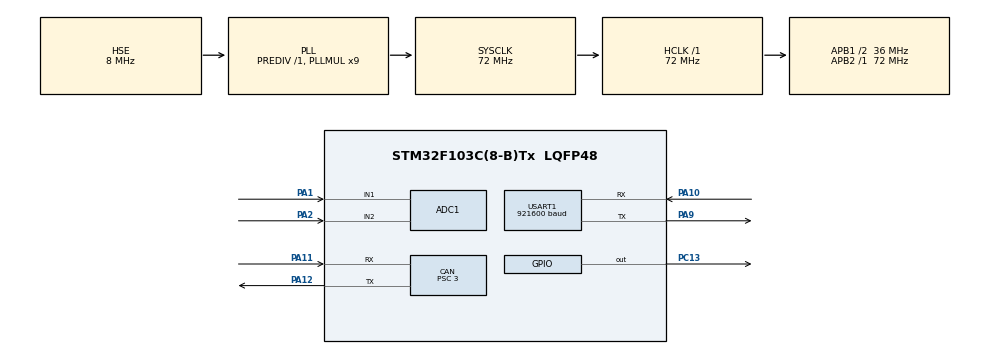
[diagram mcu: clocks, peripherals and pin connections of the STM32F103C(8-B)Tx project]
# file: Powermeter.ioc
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ADC1.Channel-4\#ChannelRegularConversion=ADC_CHANNEL_1
ADC1.Channel-5\#ChannelRegularConversion=ADC_CHANNEL_2
ADC1.Channel-6\#ChannelRegularConversion=ADC_CHANNEL_1
ADC1.ContinuousConvMode=ENABLE
ADC1.ExternalTrigConv=ADC_EXTERNALTRIGCONV_T1_CC1
ADC1.NbrOfConversion=3
ADC1.NbrOfConversionFlag=1
ADC1.Rank-4\#ChannelRegularConversion=1
ADC1.Rank-5\#ChannelRegularConversion=2
ADC1.Rank-6\#ChannelRegularConversion=3
ADC1.SamplingTime-4\#ChannelRegularConversion=ADC_SAMPLETIME_239CYCLES_5
ADC1.SamplingTime-5\#ChannelRegularConversion=ADC_SAMPLETIME_239CYCLES_5
ADC1.SamplingTime-6\#ChannelRegularConversion=ADC_SAMPLETIME_239CYCLES_5
ADC1.master=1
CAN.BS1=CAN_BS1_8TQ
CAN.BS2=CAN_BS2_3TQ
CAN.CalculateBaudRate=999999
CAN.CalculateTimeBit=1000
CAN.CalculateTimeQuantum=83.33333333333334
CAN.NART=ENABLE
CAN.Prescaler=3
Dma.ADC1.1.Direction=DMA_PERIPH_TO_MEMORY
Dma.ADC1.1.Instance=DMA1_Channel1
Dma.ADC1.1.MemDataAlignment=DMA_MDATAALIGN_HALFWORD
Dma.ADC1.1.MemInc=DMA_MINC_ENABLE
Dma.ADC1.1.Mode=DMA_CIRCULAR
Dma.ADC1.1.PeriphDataAlignment=DMA_PDATAALIGN_HALFWORD
Dma.ADC1.1.PeriphInc=DMA_PINC_DISABLE
Dma.ADC1.1.Priority=DMA_PRIORITY_LOW
Dma.Request0=USART1_TX
Dma.Request1=ADC1
Dma.USART1_TX.0.Direction=DMA_MEMORY_TO_PERIPH
Dma.USART1_TX.0.Instance=DMA1_Channel4
Dma.USART1_TX.0.MemDataAlignment=DMA_MDATAALIGN_BYTE
Dma.USART1_TX.0.MemInc=DMA_MINC_ENABLE
Dma.USART1_TX.0.Mode=DMA_NORMAL
Dma.USART1_TX.0.PeriphDataAlignment=DMA_PDATAALIGN_BYTE
Dma.USART1_TX.0.PeriphInc=DMA_PINC_DISABLE
Dma.USART1_TX.0.Priority=DMA_PRIORITY_LOW
Mcu.Family=STM32F1
Mcu.Name=STM32F103C(8-B)Tx
Mcu.Package=LQFP48
NVIC.ADC1_2_IRQn=true\:0\:0\:false\:false\:true\:true\:true\:true
NVIC.CAN1_RX1_IRQn=true\:0\:0\:false\:false\:true\:true\:true\:true
NVIC.DMA1_Channel1_IRQn=true\:0\:0\:false\:false\:true\:false\:true\:true
NVIC.DMA1_Channel4_IRQn=true\:0\:0\:false\:false\:true\:false\:true\:true
NVIC.PriorityGroup=NVIC_PRIORITYGROUP_4
NVIC.TIM1_UP_IRQn=true\:0\:0\:false\:false\:true\:true\:true\:true
NVIC.USART1_IRQn=true\:0\:0\:false\:false\:true\:true\:true\:true
NVIC.USB_HP_CAN1_TX_IRQn=true\:0\:0\:false\:false\:true\:true\:true\:true
NVIC.USB_LP_CAN1_RX0_IRQn=true\:0\:0\:false\:false\:true\:true\:true\:true
PA1.Signal=ADCx_IN1
PA10.Mode=Asynchronous
PA10.Signal=USART1_RX
PA11.GPIO_PuPd=GPIO_NOPULL
PA11.Mode=CAN_Activate
PA11.Signal=CAN_RX
PA12.Mode=CAN_Activate
PA12.Signal=CAN_TX
PA13.Mode=Serial_Wire
PA13.Signal=SYS_JTMS-SWDIO
PA14.Mode=Serial_Wire
PA14.Signal=SYS_JTCK-SWCLK
PA2.Signal=ADCx_IN2
PA9.Mode=Asynchronous
PA9.Signal=USART1_TX
PC13-TAMPER-RTC.Signal=GPIO_Output
PD0-OSC_IN.Mode=HSE-External-Oscillator
PD0-OSC_IN.Signal=RCC_OSC_IN
PD1-OSC_OUT.Mode=HSE-External-Oscillator
PD1-OSC_OUT.Signal=RCC_OSC_OUT
ProjectManager.HeapSize=0x200
ProjectManager.StackSize=0x400
ProjectManager.TargetToolchain=Makefile
RCC.ADCPresc=RCC_ADCPCLK2_DIV6
RCC.AHBFreq_Value=72000000
RCC.APB1CLKDivider=RCC_HCLK_DIV2
RCC.APB1Freq_Value=36000000
RCC.APB1TimFreq_Value=72000000
RCC.APB2Freq_Value=72000000
RCC.APB2TimFreq_Value=72000000
RCC.HCLKFreq_Value=72000000
RCC.PLLMUL=RCC_PLL_MUL9
RCC.PLLSourceVirtual=RCC_PLLSOURCE_HSE
RCC.SYSCLKFreq_VALUE=72000000
RCC.SYSCLKSource=RCC_SYSCLKSOURCE_PLLCLK
RCC.USBFreq_Value=72000000
SH.ADCx_IN1.0=ADC1_IN1,IN1
SH.ADCx_IN2.0=ADC1_IN2,IN2
TIM1.Channel-PWM\ Generation1\ No\ Output=TIM_CHANNEL_1
TIM1.Period=999
TIM1.Prescaler=71
USART1.BaudRate=921600
USART1.VirtualMode=VM_ASYNC
VP_ADC1_Vref_Input.Mode=IN-Vrefint
VP_TIM1_VS_ClockSourceINT.Mode=Internal
VP_TIM1_VS_no_output1.Mode=PWM Generation1 No Output
board=custom

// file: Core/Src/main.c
/* USER CODE BEGIN Header */
/**
  ******************************************************************************
  * @file           : main.c
  * @brief          : Main program body
  ******************************************************************************
  * @attention
  *
  * Copyright (c) 2025 STMicroelectronics.
  * All rights reserved.
  *
  * This software is licensed under terms that can be found in the LICENSE file
  * in the root directory of this software component.
  * If no LICENSE file comes with this software, it is provided AS-IS.
  *
  ******************************************************************************
  */
/* USER CODE END Header */
#include "main.h"
#include "adc.h"
#include "can.h"
#include "dma.h"
#include "tim.h"
#include "usart.h"
#include "gpio.h"
#include <math.h>

/* USER CODE BEGIN Includes */
#include "application.h"
/* USER CODE END Includes */

void SystemClock_Config(void);

/* USER CODE BEGIN 0 */

// CAN_RxHeaderTypeDef rxHeader; //CAN Bus Transmit Header
// CAN_TxHeaderTypeDef txHeader; //CAN Bus Receive Header
// uint8_t canRX[8] = {0,0,0,0,0,0,0,0};  //CAN Bus Receive Buffer
// CAN_FilterTypeDef canfil; //CAN Bus Filter
// uint32_t canMailbox; //CAN Bus Mail box variable

/* USER CODE END 0 */

int main(void)
{

  /* MCU Configuration--------------------------------------------------------*/

  /* Reset of all peripherals, Initializes the Flash interface and the Systick. */
  HAL_Init();

  /* Configure the system clock */
  SystemClock_Config();

  /* Initialize all configured peripherals */
  MX_GPIO_Init();
  MX_DMA_Init();
  MX_ADC1_Init();
  MX_CAN_Init();
  MX_USART1_UART_Init();
  MX_TIM1_Init();
  /* USER CODE BEGIN 2 */

  CAN_Init(&hcan);
  CAN_Filter_Mask_Config(&hcan, CAN_FILTER(13) | CAN_FIFO_1 | CAN_STDID | CAN_DATA_TYPE, 0x391, 0x7ff); // receive all messages with standard ID and data frame
  HAL_CAN_ActivateNotification(&hcan,CAN_IT_RX_FIFO0_MSG_PENDING);
  // uint8_t send_data = 0;

  controller_init();
  // begin ADC:
  HAL_ADCEx_Calibration_Start(&hadc1);
  HAL_ADC_Start_DMA(&hadc1, (uint32_t*)adc1_buffer, 3);

  HAL_TIM_Base_Start_IT(&htim1);

  /* USER CODE END 2 */

  /* Infinite loop */
  while (1)
  {

  }
}

void SystemClock_Config(void)
{
  RCC_OscInitTypeDef RCC_OscInitStruct = {0};
  RCC_ClkInitTypeDef RCC_ClkInitStruct = {0};
  RCC_PeriphCLKInitTypeDef PeriphClkInit = {0};

  /** Initializes the RCC Oscillators according to the specified parameters
  * in the RCC_OscInitTypeDef structure.
  */
  RCC_OscInitStruct.OscillatorType = RCC_OSCILLATORTYPE_HSE;
  RCC_OscInitStruct.HSEState = RCC_HSE_ON;
  RCC_OscInitStruct.HSEPredivValue = RCC_HSE_PREDIV_DIV1;
  RCC_OscInitStruct.HSIState = RCC_HSI_ON;
  RCC_OscInitStruct.PLL.PLLState = RCC_PLL_ON;
  RCC_OscInitStruct.PLL.PLLSource = RCC_PLLSOURCE_HSE;
  RCC_OscInitStruct.PLL.PLLMUL = RCC_PLL_MUL9;
  if (HAL_RCC_OscConfig(&RCC_OscInitStruct) != HAL_OK)
  {
    Error_Handler();
  }

  /** Initializes the CPU, AHB and APB buses clocks
  */
  RCC_ClkInitStruct.ClockType = RCC_CLOCKTYPE_HCLK|RCC_CLOCKTYPE_SYSCLK
                              |RCC_CLOCKTYPE_PCLK1|RCC_CLOCKTYPE_PCLK2;
  RCC_ClkInitStruct.SYSCLKSource = RCC_SYSCLKSOURCE_PLLCLK;
  RCC_ClkInitStruct.AHBCLKDivider = RCC_SYSCLK_DIV1;
  RCC_ClkInitStruct.APB1CLKDivider = RCC_HCLK_DIV2;
  RCC_ClkInitStruct.APB2CLKDivider = RCC_HCLK_DIV1;

  if (HAL_RCC_ClockConfig(&RCC_ClkInitStruct, FLASH_LATENCY_2) != HAL_OK)
  {
    Error_Handler();
  }
  PeriphClkInit.PeriphClockSelection = RCC_PERIPHCLK_ADC;
  PeriphClkInit.AdcClockSelection = RCC_ADCPCLK2_DIV6;
  if (HAL_RCCEx_PeriphCLKConfig(&PeriphClkInit) != HAL_OK)
  {
    Error_Handler();
  }
}

/* USER CODE BEGIN 4 */
// void HAL_CAN_RxFifo0MsgPendingCallback(CAN_HandleTypeDef *hcan1)
// {
// 	HAL_CAN_GetRxMessage(hcan1, CAN_RX_FIFO0, &rxHeader, canRX);
// 	HAL_GPIO_TogglePin(GPIOA, GPIO_PIN_3);

// }
/* USER CODE END 4 */

void Error_Handler(void)
{
  __disable_irq();
  while (1)
  {
  }
}
